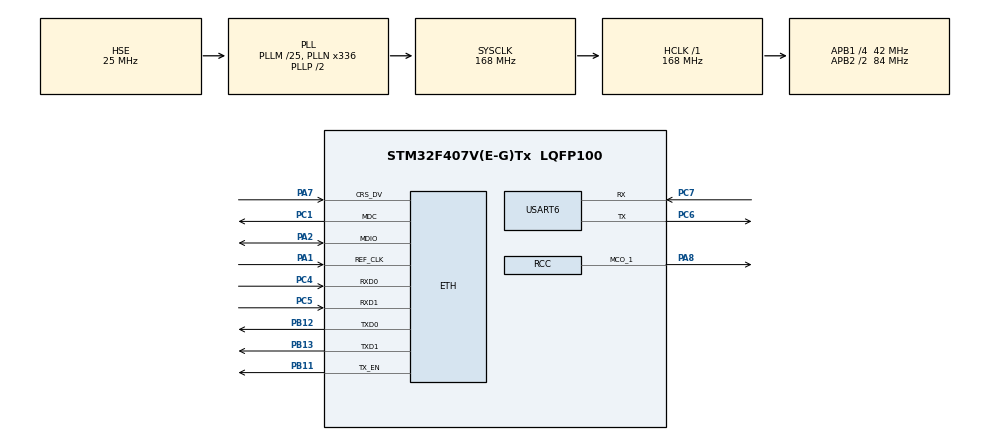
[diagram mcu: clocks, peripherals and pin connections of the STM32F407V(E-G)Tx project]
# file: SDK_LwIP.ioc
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ETH.MediaInterface=ETH_MEDIA_INTERFACE_RMII
ETH.PHY_ISFR_INT4=0x0010
ETH.PHY_Name_RMII=LAN8742A_PHY_ADDRESS
ETH.PhyAddress=0
FREERTOS.MEMORY_ALLOCATION=0
FREERTOS.Tasks01=defaultTask,0,128,StartDefaultTask,Default,NULL,Dynamic,NULL,NULL
FREERTOS.configTOTAL_HEAP_SIZE=20000
LWIP.IP_ADDRESS=000.000.000.000
LWIP.LWIP_DHCP=0
LWIP.LWIP_HTTPD=0
LWIP.NETMASK_ADDRESS=000.000.000.000
LWIP.Version=v2.0.3_Cube
Mcu.Family=STM32F4
Mcu.Name=STM32F407V(E-G)Tx
Mcu.Package=LQFP100
NVIC.ETH_IRQn=true\:5\:0\:false\:false\:true\:true\:false\:true
NVIC.PriorityGroup=NVIC_PRIORITYGROUP_4
NVIC.TIM1_UP_TIM10_IRQn=true\:0\:0\:false\:false\:true\:false\:false\:true
NVIC.TimeBase=TIM1_UP_TIM10_IRQn
NVIC.TimeBaseIP=TIM1
PA1.Mode=RMII
PA1.Signal=ETH_REF_CLK
PA13.Mode=JTAG_5_pins
PA13.Signal=SYS_JTMS-SWDIO
PA14.Mode=JTAG_5_pins
PA14.Signal=SYS_JTCK-SWCLK
PA15.Mode=JTAG_5_pins
PA15.Signal=SYS_JTDI
PA2.Mode=RMII
PA2.Signal=ETH_MDIO
PA7.Mode=RMII
PA7.Signal=ETH_CRS_DV
PA8.Mode=Clock-out-1
PA8.Signal=RCC_MCO_1
PB11.Mode=RMII
PB11.Signal=ETH_TX_EN
PB12.Mode=RMII
PB12.Signal=ETH_TXD0
PB13.Mode=RMII
PB13.Signal=ETH_TXD1
PB3.Mode=JTAG_5_pins
PB3.Signal=SYS_JTDO-SWO
PB4.Mode=JTAG_5_pins
PB4.Signal=SYS_JTRST
PB8.Signal=I2C1_SCL
PB9.Signal=I2C1_SDA
PC1.Mode=RMII
PC1.Signal=ETH_MDC
PC4.Mode=RMII
PC4.Signal=ETH_RXD0
PC5.Mode=RMII
PC5.Signal=ETH_RXD1
PC6.Mode=Asynchronous
PC6.Signal=USART6_TX
PC7.Mode=Asynchronous
PC7.Signal=USART6_RX
PH0-OSC_IN.Mode=HSE-External-Oscillator
PH0-OSC_IN.Signal=RCC_OSC_IN
PH1-OSC_OUT.Mode=HSE-External-Oscillator
PH1-OSC_OUT.Signal=RCC_OSC_OUT
ProjectManager.HeapSize=0x200
ProjectManager.StackSize=0x400
ProjectManager.TargetToolchain=SW4STM32
RCC.48MHZClocksFreq_Value=84000000
RCC.AHBFreq_Value=168000000
RCC.APB1CLKDivider=RCC_HCLK_DIV4
RCC.APB1Freq_Value=42000000
RCC.APB1TimFreq_Value=84000000
RCC.APB2CLKDivider=RCC_HCLK_DIV2
RCC.APB2Freq_Value=84000000
RCC.APB2TimFreq_Value=168000000
RCC.CortexFreq_Value=168000000
RCC.EnbaleCSS=true
RCC.HCLKFreq_Value=168000000
RCC.HSE_VALUE=25000000
RCC.HSI_VALUE=16000000
RCC.LSE_VALUE=32768
RCC.PLLM=25
RCC.PLLN=336
RCC.PLLSourceVirtual=RCC_PLLSOURCE_HSE
RCC.RCC_MCO1Source=RCC_MCO1SOURCE_HSE
RCC.SYSCLKFreq_VALUE=168000000
RCC.SYSCLKSource=RCC_SYSCLKSOURCE_PLLCLK
RCC.VCOOutputFreq_Value=336000000
USART6.VirtualMode=VM_ASYNC
VP_FREERTOS_VS_CMSIS_V1.Mode=CMSIS_V1
VP_LWIP_VS_Enabled.Mode=Enabled
VP_SYS_VS_tim1.Mode=TIM1
board=custom

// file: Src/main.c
/* USER CODE BEGIN Header */
/**
  ******************************************************************************
  * @file           : main.c
  * @brief          : Main program body
  ******************************************************************************
  * @attention
  *
  * <h2><center>&copy; Copyright (c) 2019 STMicroelectronics.
  * All rights reserved.</center></h2>
  *
  * This software component is licensed by ST under Ultimate Liberty license
  * SLA0044, the "License"; You may not use this file except in compliance with
  * the License. You may obtain a copy of the License at:
  *                             www.st.com/SLA0044
  *
  ******************************************************************************
  */
/* USER CODE END Header */

#include "main.h"
#include "cmsis_os.h"
#include "lwip.h"
#include "usart.h"
#include "gpio.h"

void SystemClock_Config(void);
void MX_FREERTOS_Init(void);

int main(void)
{

  /* MCU Configuration--------------------------------------------------------*/

  /* Reset of all peripherals, Initializes the Flash interface and the Systick. */
  HAL_Init();

  /* Configure the system clock */
  SystemClock_Config();

  /* Initialize all configured peripherals */
  MX_GPIO_Init();
  MX_USART6_UART_Init();

  /* Call init function for freertos objects (in freertos.c) */
  MX_FREERTOS_Init();

  /* Start scheduler */
  osKernelStart();

  /* We should never get here as control is now taken by the scheduler */

  /* Infinite loop */
  while (1)
  {

  }
}

void SystemClock_Config(void)
{
  RCC_OscInitTypeDef RCC_OscInitStruct = {0};
  RCC_ClkInitTypeDef RCC_ClkInitStruct = {0};

  /** Configure the main internal regulator output voltage
  */
  __HAL_RCC_PWR_CLK_ENABLE();
  __HAL_PWR_VOLTAGESCALING_CONFIG(PWR_REGULATOR_VOLTAGE_SCALE1);
  /** Initializes the CPU, AHB and APB busses clocks
  */
  RCC_OscInitStruct.OscillatorType = RCC_OSCILLATORTYPE_HSE;
  RCC_OscInitStruct.HSEState = RCC_HSE_ON;
  RCC_OscInitStruct.PLL.PLLState = RCC_PLL_ON;
  RCC_OscInitStruct.PLL.PLLSource = RCC_PLLSOURCE_HSE;
  RCC_OscInitStruct.PLL.PLLM = 25;
  RCC_OscInitStruct.PLL.PLLN = 336;
  RCC_OscInitStruct.PLL.PLLP = RCC_PLLP_DIV2;
  RCC_OscInitStruct.PLL.PLLQ = 4;
  if (HAL_RCC_OscConfig(&RCC_OscInitStruct) != HAL_OK)
  {
    Error_Handler();
  }
  /** Initializes the CPU, AHB and APB busses clocks
  */
  RCC_ClkInitStruct.ClockType = RCC_CLOCKTYPE_HCLK|RCC_CLOCKTYPE_SYSCLK
                              |RCC_CLOCKTYPE_PCLK1|RCC_CLOCKTYPE_PCLK2;
  RCC_ClkInitStruct.SYSCLKSource = RCC_SYSCLKSOURCE_PLLCLK;
  RCC_ClkInitStruct.AHBCLKDivider = RCC_SYSCLK_DIV1;
  RCC_ClkInitStruct.APB1CLKDivider = RCC_HCLK_DIV4;
  RCC_ClkInitStruct.APB2CLKDivider = RCC_HCLK_DIV2;

  if (HAL_RCC_ClockConfig(&RCC_ClkInitStruct, FLASH_LATENCY_5) != HAL_OK)
  {
    Error_Handler();
  }
  HAL_RCC_MCOConfig(RCC_MCO1, RCC_MCO1SOURCE_HSE, RCC_MCODIV_1);
  /** Enables the Clock Security System
  */
  HAL_RCC_EnableCSS();
}

void HAL_TIM_PeriodElapsedCallback(TIM_HandleTypeDef *htim)
{
  if (htim->Instance == TIM1) {
    HAL_IncTick();
  }
}

void Error_Handler(void)
{
}

/************************ (C) COPYRIGHT STMicroelectronics *****END OF FILE****/

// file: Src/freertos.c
/* USER CODE BEGIN Header */
/**
  ******************************************************************************
  * File Name          : freertos.c
  * Description        : Code for freertos applications
  ******************************************************************************
  * @attention
  *
  * <h2><center>&copy; Copyright (c) 2019 STMicroelectronics.
  * All rights reserved.</center></h2>
  *
  * This software component is licensed by ST under Ultimate Liberty license
  * SLA0044, the "License"; You may not use this file except in compliance with
  * the License. You may obtain a copy of the License at:
  *                             www.st.com/SLA0044
  *
  ******************************************************************************
  */
/* USER CODE END Header */

#include "FreeRTOS.h"
#include "task.h"
#include "main.h"
#include "cmsis_os.h"

/* USER CODE BEGIN Includes */
#include "usart.h"
#include "ethernetif.h"
#include "tcpecho.h"
/* USER CODE END Includes */

osThreadId defaultTaskHandle;

void StartDefaultTask(void const * argument);

extern void MX_LWIP_Init(void);
void MX_FREERTOS_Init(void); /* (MISRA C 2004 rule 8.1) */

void MX_FREERTOS_Init(void) {

  /* Create the thread(s) */
  /* definition and creation of defaultTask */
  osThreadDef(defaultTask, StartDefaultTask, osPriorityNormal, 0, 128);
  defaultTaskHandle = osThreadCreate(osThread(defaultTask), NULL);

}

void StartDefaultTask(void const * argument)
{
  /* init code for LWIP */
  MX_LWIP_Init();

  /* USER CODE BEGIN StartDefaultTask */
  tcpecho();	//start tcp echo
  /* Infinite loop */
  for(;;)
  {
    osDelay(1);
  }
  /* USER CODE END StartDefaultTask */
}

/************************ (C) COPYRIGHT STMicroelectronics *****END OF FILE****/
